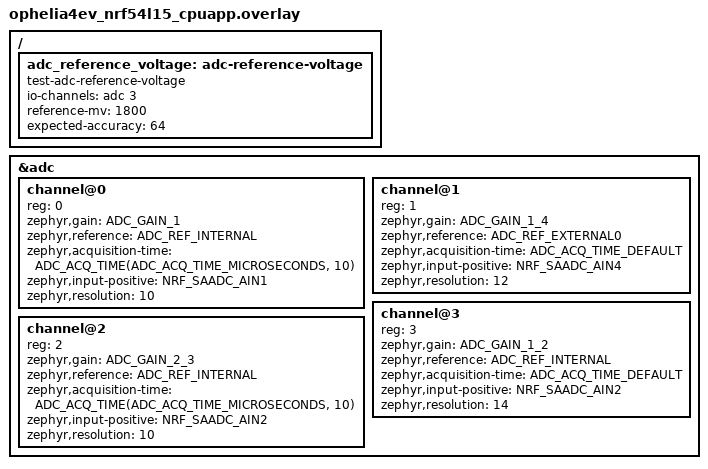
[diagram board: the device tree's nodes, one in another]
/*
 * SPDX-License-Identifier: Apache-2.0
 *
 * Copyright (c) 2025 Würth Elektronik eiSos GmbH & Co. KG
 */

&adc {
	#address-cells = <1>;
	#size-cells = <0>;

	channel@0 {
		reg = <0>;
		zephyr,gain = "ADC_GAIN_1";
		zephyr,reference = "ADC_REF_INTERNAL";
		zephyr,acquisition-time = <ADC_ACQ_TIME(ADC_ACQ_TIME_MICROSECONDS, 10)>;
		zephyr,input-positive = <NRF_SAADC_AIN1>;
		zephyr,resolution = <10>;
	};

	channel@1 {
		reg = <1>;
		zephyr,gain = "ADC_GAIN_1_4";
		zephyr,reference = "ADC_REF_EXTERNAL0";
		zephyr,acquisition-time = <ADC_ACQ_TIME_DEFAULT>;
		zephyr,input-positive = <NRF_SAADC_AIN4>;
		zephyr,resolution = <12>;
	};

	channel@2 {
		reg = <2>;
		zephyr,gain = "ADC_GAIN_2_3";
		zephyr,reference = "ADC_REF_INTERNAL";
		zephyr,acquisition-time = <ADC_ACQ_TIME(ADC_ACQ_TIME_MICROSECONDS, 10)>;
		zephyr,input-positive = <NRF_SAADC_AIN2>;
		zephyr,resolution = <10>;
	};

	channel@3 {
		reg = <3>;
		zephyr,gain = "ADC_GAIN_1_2";
		zephyr,reference = "ADC_REF_INTERNAL";
		zephyr,acquisition-time = <ADC_ACQ_TIME_DEFAULT>;
		zephyr,input-positive = <NRF_SAADC_AIN2>;
		zephyr,resolution = <14>;
	};
};

/ {
	adc_reference_voltage: adc-reference-voltage {
		compatible = "test-adc-reference-voltage";
		io-channels = <&adc 3>;
		reference-mv = <1800>;
		expected-accuracy = <64>;
	};
};
